# S32M24x register map
Vendor: NXP Semiconductors; File version: 1.3
S32M24x NXP Microcontroller
CPU: CM4 r0p1, little endian, MPU, FPU, VTOR, 4 interrupt priority bits
Registers are 32-bit, read-write, reset 0x0 unless marked. A register's access mark holds for its fields unless they carry their own. Offsets are from the block's base; lines under a group give offsets from that group; [hi:lo] are bit positions; {n}, {i} and the like mark numbered series; 'fields as' and 'values as' point back to an identical list; <NAME> marks a mode.

## Memory map
0x00000000 AEC_AE size 0x100 — AEC
0x00000100 PMC_AE size 0x10 — PMC
0x00000120 MEM_OTP_AE size 0x20 — MEM_OTP
0x00000140 DPGA_AE size 0x10 — DPGA
0x00000180 GDU_AE size 0x190 — GDU
0x00000200 HVI_AE size 0x1B — HVM
0x40000000 AIPS size 0x70
0x40001000 MSCM size 0x40C
0x40008000 DMA size 0x1200
0x4000D000 MPU size 0x820
0x40018000 ERM size 0x114
0x40019000 EIM size 0x148
0x40020000 FTFC size 0x30
0x40020000 FTFM size 0x30
0x40021000 DMAMUX size 0x10
0x40024000 FLEXCAN0 size 0xC0C — CAN
0x40026000 FTM3 size 0xBC — FTM
0x40027000 ADC1 size 0xEC — ADC
0x4002C000 LPSPI0 size 0x78 — LPSPI
0x4002D000 LPSPI1 size 0x78 — LPSPI
0x4002E000 LPSPI2 size 0x78 — LPSPI
0x40031000 PDB1 size 0x198 — PDB
0x40032000 CRC size 0xC
0x40036000 PDB0 size 0x198 — PDB
0x40037000 LPIT0 size 0x5C — LPIT
0x40038000 FTM0 size 0xBC — FTM
0x40039000 FTM1 size 0x224 — FTM
0x4003A000 FTM2 size 0x224 — FTM
0x4003B000 ADC0 size 0xEC — ADC
0x4003D000 RTC size 0x20
0x40040000 LPTMR0 size 0x10 — LPTMR
0x40048000 SIM size 0x70
0x40049000 PORTA size 0xCC — PORT
0x4004A000 PORTB size 0xCC — PORT
0x4004B000 PORTC size 0xCC — PORT
0x4004C000 PORTD size 0xCC — PORT
0x4004D000 PORTE size 0xCC — PORT
0x40052000 WDOG size 0x10
0x4005A000 FLEXIO size 0x510
0x40061000 EWM size 0x6
0x40063000 TRGMUX size 0x68
0x40064000 SCG size 0x60C
0x40065000 PCC size 0x1D0
0x40066000 LPI2C0 size 0x174 — LPI2C
0x4006A000 LPUART0 size 0x30 — LPUART
0x4006B000 LPUART1 size 0x30 — LPUART
0x40073000 CMP0 size 0xC — CMP
0x4007D000 PMC size 0x5
0x4007D000 PMC_142 size 0x5 — PMC
0x4007E000 SMC size 0x18
0x4007F000 RCM size 0x20
0x400FF000 PTA size 0x1C — GPIO
0x400FF040 PTB size 0x1C — GPIO
0x400FF080 PTC size 0x1C — GPIO
0x400FF0C0 PTD size 0x1C — GPIO
0x400FF100 PTE size 0x1C — GPIO
0xE0080000 MCM size 0x4A8
0xE0082000 LMEM size 0x24

## MEM_OTP_AE — MEM_OTP
Base 0x00000120
0x00 CTRL_CMD 16-bit — Control Command
  [5:0] CMD — Command
    11=RD_ONE (OTPC_C_RD_ONE)
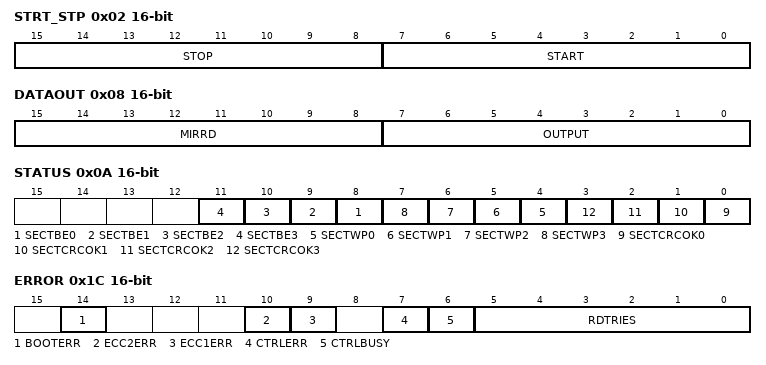
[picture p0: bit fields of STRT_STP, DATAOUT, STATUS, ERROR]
0x02 STRT_STP 16-bit — Start Stop
  [15:8] STOP, [7:0] START
0x08 DATAOUT 16-bit ro — Data Output
  [15:8] MIRRD — Mirror Read Direct
  [7:0] OUTPUT
0x0A STATUS 16-bit ro
  [n+8] SECTBE{n} (n=0..3) — Sector Boot Enable
    0=DISABLED; 1=ENABLED
  [n+4] SECTWP{n} (n=0..3) — Sector Write Protect
    0=NOTPROTECTED; 1=PROTECTED
  [n] SECTCRCOK{n} (n=0..3) — Sector CRC OK
    0=ERROR (CRC error or CRC not verified); 1=NOERROR (No CRC error)
0x1C ERROR 16-bit ro
  [14] BOOTERR — Boot Error
    0=NOERROR; 1=ERROR
  [10] ECC2ERR — ECC 2-bit Error
    0=NOERROR; 1=ERROR
  [9] ECC1ERR — ECC 1-bit Error
    0=NOERROR; 1=ERROR
  [7] CTRLERR — Error
  [6] CTRLBUSY — Busy
    0=IDLE; 1=EXECUTING (Executing a command or booting the OTP)
  [5:0] RDTRIES — ROM Reads
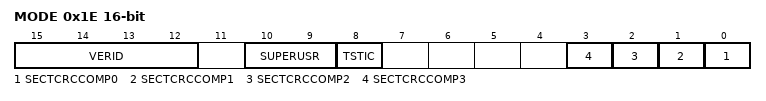
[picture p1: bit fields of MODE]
0x1E MODE 16-bit ro
  [15:12] VERID — Version Identifier
  [10:9] SUPERUSR — Superuser Mode
    0=USER (User mode); 1=SUPERUSER (Superuser mode)
  [8] TSTIC — IC Test
    0=NORMAL (Normal operation); 1=TEST (IC Test mode)
  [n] SECTCRCCOMP{n} (n=0..3) — Sector CRC Check Complete
    0=NOTCOMPLETED; 1=COMPLETED

## Licence text in the file
Copyright 2016-2023 NXP NXP Confidential. This software is owned or controlled by NXP and may only be used strictly in accordance with the applicable license terms. By expressly accepting such terms or by downloading, installing, activating and/or otherwise using the software, you are agreeing that you have read, and that you agree to comply with and are bound by, such license terms. If you do not agree to be bound by the applicable license terms, then you may not retain, install, activate or otherwise use the software.
